# ATSAMA5D31 device description
Architecture: CORTEX-A5; Family: SAMA5
Registers are 32-bit, read-write, no defined reset value unless marked. A register's access mark holds for its fields unless they carry their own. Offsets are from the block's base; [hi:lo] are bit positions; {n}, {i} and the like mark numbered series; 'fields as' and 'values as' point back to an identical list.

## EMAC — Ethernet MAC 10/100
Instances: EMAC 0xF802C000
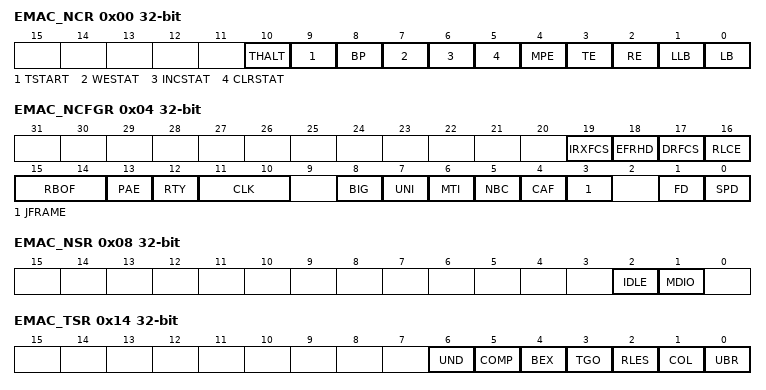
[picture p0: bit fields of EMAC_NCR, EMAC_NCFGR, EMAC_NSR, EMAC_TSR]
0x00 EMAC_NCR — Network Control Register
  [10] THALT — Transmit halt
  [9] TSTART — Start transmission
  [8] BP — Back pressure
  [7] WESTAT — Write enable for statistics registers
  [6] INCSTAT — Increment statistics registers
  [5] CLRSTAT — Clear statistics registers
  [4] MPE — Management port enable
  [3] TE — Transmit enable
  [2] RE — Receive enable
  [1] LLB — Loopback local
  [0] LB — LoopBack
0x04 EMAC_NCFGR — Network Configuration Register
  [19] IRXFCS — Ignore RX FCS
  [18] EFRHD
  [17] DRFCS — Discard Receive FCS
  [16] RLCE — Receive Length field Checking Enable
  [15:14] RBOF — Receive Buffer Offset
    0=OFFSET_0 (No offset from start of receive buffer.); 1=OFFSET_1 (One-byte offset from start of receive buffer.); 2=OFFSET_2 (Two-byte offset from start of receive buffer.); 3=OFFSET_3 (Three-byte offset from start of receive buffer.)
  [13] PAE — Pause Enable
  [12] RTY — Retry test
  [11:10] CLK — MDC clock divider
    0=MCK_8 (MCK divided by 8 (MCK up to 20 MHz).); 1=MCK_16 (MCK divided by 16 (MCK up to 40 MHz).); 2=MCK_32 (MCK divided by 32 (MCK up to 80 MHz).); 3=MCK_64 (MCK divided by 64 (MCK up to 160 MHz).)
  [8] BIG — Receive 1536 bytes frames
  [7] UNI — Unicast Hash Enable
  [6] MTI — Multicast Hash Enable
  [5] NBC — No Broadcast
  [4] CAF — Copy All Frames
  [3] JFRAME — Jumbo Frames
  [1] FD — Full Duplex
  [0] SPD — Speed
0x08 EMAC_NSR ro — Network Status Register
  [2] IDLE, [1] MDIO
0x14 EMAC_TSR — Transmit Status Register
  [6] UND — Transmit Underrun
  [5] COMP — Transmit Complete
  [4] BEX — Buffers exhausted mid frame
  [3] TGO — Transmit Go
  [2] RLES — Retry Limit exceeded
  [1] COL — Collision Occurred
  [0] UBR — Used Bit Read
0x18 EMAC_RBQP — Receive Buffer Queue Pointer Register
  [31:2] ADDR — Receive buffer queue pointer address
0x1C EMAC_TBQP — Transmit Buffer Queue Pointer Register
  [31:2] ADDR — Transmit buffer queue pointer address
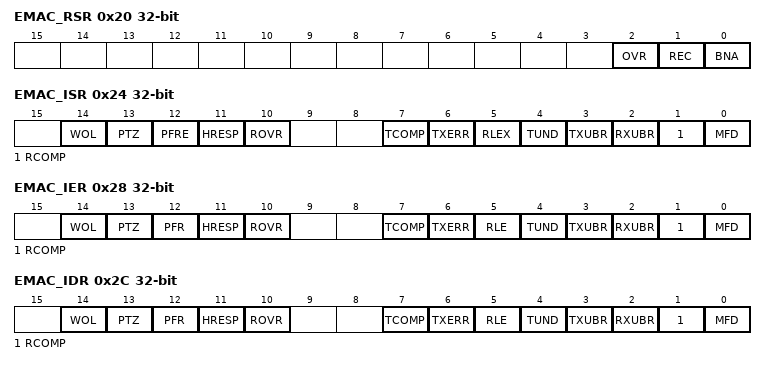
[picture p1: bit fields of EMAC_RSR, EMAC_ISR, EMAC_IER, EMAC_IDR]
0x20 EMAC_RSR — Receive Status Register
  [2] OVR — Receive Overrun
  [1] REC — Frame Received
  [0] BNA — Buffer Not Available
0x24 EMAC_ISR — Interrupt Status Register
  [14] WOL — Wake On LAN
  [13] PTZ — Pause Time Zero
  [12] PFRE — Pause Frame Received
  [11] HRESP — Hresp not OK
  [10] ROVR — Receive Overrun
  [7] TCOMP — Transmit Complete
  [6] TXERR — Transmit Error
  [5] RLEX — Retry Limit Exceeded
  [4] TUND — Ethernet Transmit Buffer Underrun
  [3] TXUBR — Transmit Used Bit Read
  [2] RXUBR — Receive Used Bit Read
  [1] RCOMP — Receive Complete
  [0] MFD — Management Frame Done
0x28 EMAC_IER wo — Interrupt Enable Register
  [14] WOL — Wake On LAN
  [13] PTZ — Pause Time Zero
  [12] PFR — Pause Frame Received
  [11] HRESP — Hresp not OK
  [10] ROVR — Receive Overrun
  [7] TCOMP — Transmit Complete
  [6] TXERR
  [5] RLE — Retry Limit Exceeded
  [4] TUND — Ethernet Transmit Buffer Underrun
  [3] TXUBR — Transmit Used Bit Read
  [2] RXUBR — Receive Used Bit Read
  [1] RCOMP — Receive Complete
  [0] MFD — Management Frame sent
0x2C EMAC_IDR wo — Interrupt Disable Register
  fields as EMAC_IER
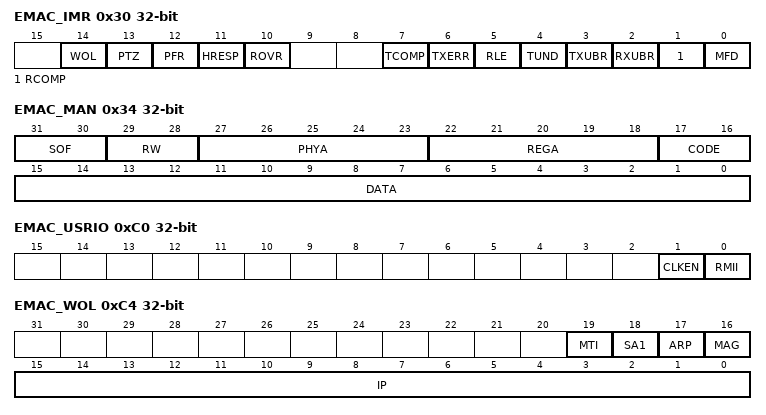
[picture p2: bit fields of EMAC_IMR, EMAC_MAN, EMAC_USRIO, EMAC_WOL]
0x30 EMAC_IMR ro — Interrupt Mask Register
  fields as EMAC_IER
0x34 EMAC_MAN — Phy Maintenance Register
  [31:30] SOF — Start of frame
  [29:28] RW — Read-write
  [27:23] PHYA — PHY Address
  [22:18] REGA — Register Address
  [17:16] CODE
  [15:0] DATA
0x38 EMAC_PTR — Pause Time Register
  [15:0] PTIME — Pause Time
0x3C EMAC_PFR — Pause Frames Received Register
  [15:0] FROK — Pause Frames received OK
0x40 EMAC_FTO — Frames Transmitted Ok Register
  [23:0] FTOK — Frames Transmitted OK
0x44 EMAC_SCF — Single Collision Frames Register
  [15:0] SCF — Single Collision Frames
0x48 EMAC_MCF — Multiple Collision Frames Register
  [15:0] MCF — Multicollision Frames
0x4C EMAC_FRO — Frames Received Ok Register
  [23:0] FROK — Frames Received OK
0x50 EMAC_FCSE — Frame Check Sequence Errors Register
  [7:0] FCSE — Frame Check Sequence Errors
0x54 EMAC_ALE — Alignment Errors Register
  [7:0] ALE — Alignment Errors
0x58 EMAC_DTF — Deferred Transmission Frames Register
  [15:0] DTF — Deferred Transmission Frames
0x5C EMAC_LCOL — Late Collisions Register
  [7:0] LCOL — Late Collisions
0x60 EMAC_ECOL — Excessive Collisions Register
  [7:0] EXCOL — Excessive Collisions
0x64 EMAC_TUND — Transmit Underrun Errors Register
  [7:0] TUND — Transmit Underruns
0x68 EMAC_CSE — Carrier Sense Errors Register
  [7:0] CSE — Carrier Sense Errors
0x6C EMAC_RRE — Receive Resource Errors Register
  [15:0] RRE — Receive Resource Errors
0x70 EMAC_ROV — Receive Overrun Errors Register
  [7:0] ROVR — Receive Overrun
0x74 EMAC_RSE — Receive Symbol Errors Register
  [7:0] RSE — Receive Symbol Errors
0x78 EMAC_ELE — Excessive Length Errors Register
  [7:0] EXL — Excessive Length Errors
0x7C EMAC_RJA — Receive Jabbers Register
  [7:0] RJB — Receive Jabbers
0x80 EMAC_USF — Undersize Frames Register
  [7:0] USF — Undersize frames
0x84 EMAC_STE — SQE Test Errors Register
  [7:0] SQER — SQE test errors
0x88 EMAC_RLE — Received Length Field Mismatch Register
  [7:0] RLFM — Receive Length Field Mismatch
0x90 EMAC_HRB — Hash Register Bottom [31:0] Register
  [31:0] ADDR
0x94 EMAC_HRT — Hash Register Top [63:32] Register
  [31:0] ADDR
{0x90+8i} EMAC_SA{i}B (i=1..4) — Specific Address {i} Bottom Register
  [31:0] ADDR
{0x94+8i} EMAC_SA{i}T (i=1..4) — Specific Address {i} Top Register
  [15:0] ADDR
0xB8 EMAC_TID — Type ID Checking Register
  [15:0] TID — Type ID checking
0xC0 EMAC_USRIO — User Input/Output Register
  [1] CLKEN — Clock Enable
  [0] RMII — Reduce MII
0xC4 EMAC_WOL — Wake on LAN Register
  [19] MTI — Multicast hash event enable
  [18] SA1 — Specific address register 1 event enable
  [17] ARP — ARP request IP address
  [16] MAG — Magic packet event enable
  [15:0] IP — ARP request IP address

## Notices in the file
Copyright (c) 2012, Atmel Corporation
All rights reserved.
Redistribution and use in source and binary forms, with or without
modification, are permitted provided that the following condition is met:
- Redistributions of source code must retain the above copyright notice,
this list of conditions and the disclaimer below.
Atmel's name may not be used to endorse or promote products derived from
this software without specific prior written permission.
DISCLAIMER: THIS SOFTWARE IS PROVIDED BY ATMEL "AS IS" AND ANY EXPRESS OR
IMPLIED WARRANTIES, INCLUDING, BUT NOT LIMITED TO, THE IMPLIED WARRANTIES OF
MERCHANTABILITY, FITNESS FOR A PARTICULAR PURPOSE AND NON-INFRINGEMENT ARE
DISCLAIMED. IN NO EVENT SHALL ATMEL BE LIABLE FOR ANY DIRECT, INDIRECT,
INCIDENTAL, SPECIAL, EXEMPLARY, OR CONSEQUENTIAL DAMAGES (INCLUDING, BUT NOT
LIMITED TO, PROCUREMENT OF SUBSTITUTE GOODS OR SERVICES; LOSS OF USE, DATA,
OR PROFITS; OR BUSINESS INTERRUPTION) HOWEVER CAUSED AND ON ANY THEORY OF
LIABILITY, WHETHER IN CONTRACT, STRICT LIABILITY, OR TORT (INCLUDING
NEGLIGENCE OR OTHERWISE) ARISING IN ANY WAY OUT OF THE USE OF THIS SOFTWARE,
EVEN IF ADVISED OF THE POSSIBILITY OF SUCH DAMAGE.
